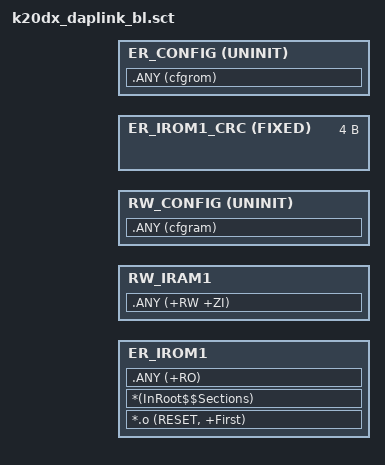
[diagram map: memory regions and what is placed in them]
#! armcc -E

#include "../daplink_addr.h"

LR_IROM1 DAPLINK_ROM_BL_START DAPLINK_ROM_BL_SIZE {  ; load region size_region

  ER_IROM1 DAPLINK_ROM_BL_START DAPLINK_ROM_BL_SIZE {  ; load address = execution address
   *.o (RESET, +First)
   *(InRoot$$Sections)
   .ANY (+RO)
  }

  RW_IRAM1 DAPLINK_RAM_APP_START DAPLINK_RAM_APP_SIZE {  ; RW data
   .ANY (+RW +ZI)
  }

  RW_CONFIG DAPLINK_RAM_SHARED_START UNINIT DAPLINK_RAM_SHARED_SIZE {
    .ANY (cfgram)
  }

  ER_IROM1_CRC (DAPLINK_ROM_BL_START + DAPLINK_ROM_BL_SIZE - 4) FIXED FILL 0xFFFFFFFF 4 {
    ; reserve space for the CRC
  }
}
LR_CONFIG DAPLINK_ROM_CONFIG_USER_START DAPLINK_ROM_CONFIG_USER_SIZE {  ; reserve last sector for config data
  ER_CONFIG DAPLINK_ROM_CONFIG_USER_START UNINIT DAPLINK_ROM_CONFIG_USER_SIZE {
    .ANY (cfgrom)
  }
}
